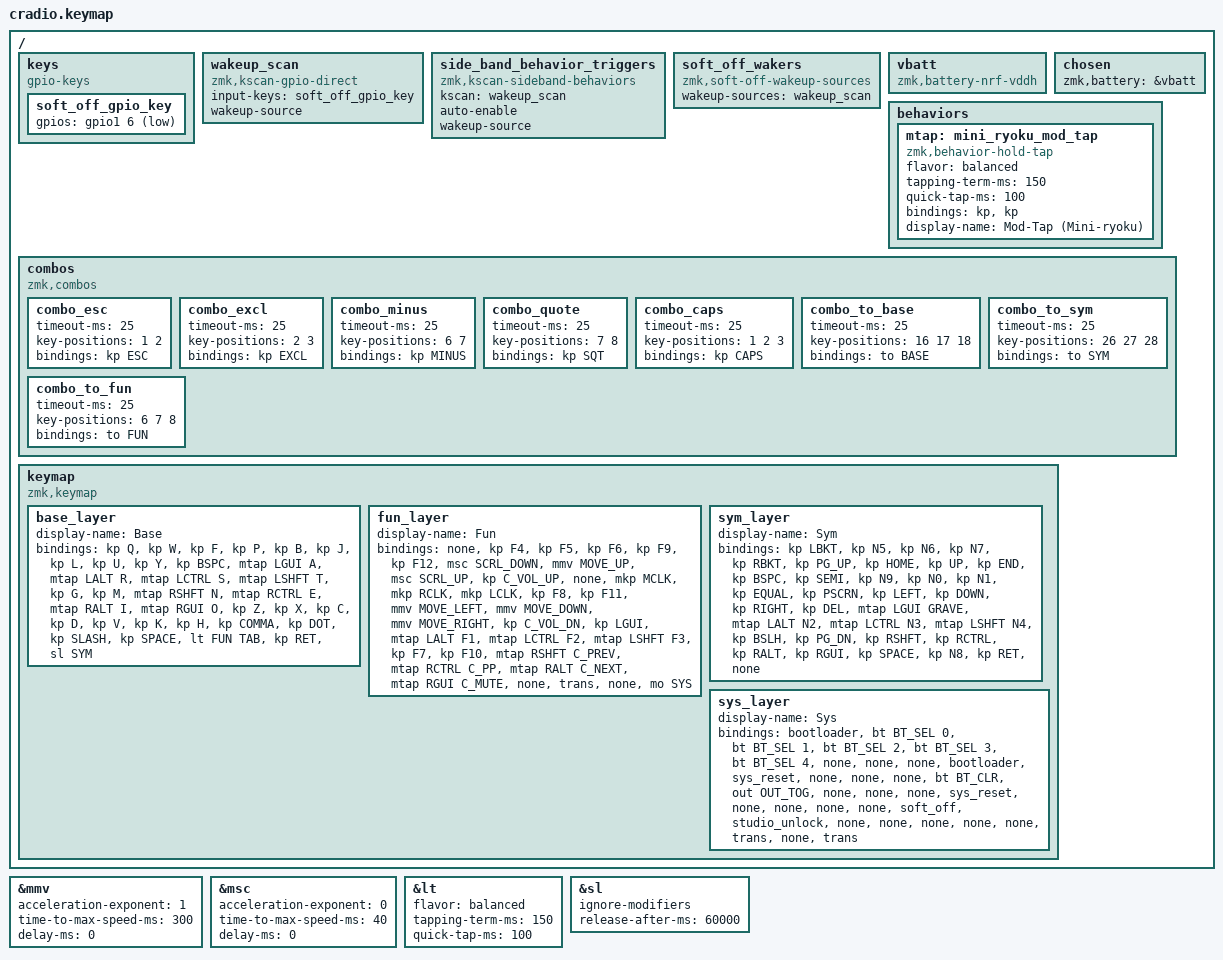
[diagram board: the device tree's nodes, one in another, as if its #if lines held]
// Mini-ryoku for the Ferris Sweep (cradio), ZMK port.
//
// Layout: Mini-ryoku by ChuseCubr, a 34-key adaptation of Miryoku.
//   https://github.com/ChuseCubr/mini-ryoku (branch `combos`, commit 7a710dd)
//   Copyright 2023 ChuseCubr, GPL-2.0-or-later.
// This file is a hand port of its QMK keymap (qmk/layout.h, keycodes.h,
// combos.c, config.h) to ZMK, and is distributed under the same licence:
// GNU General Public License, version 2 or (at your option) any later version.
// Deviations from upstream are listed in README.md.
//
// Hardware nodes (soft-off wakeup, battery) and pointer speed come from the
// NXTKB Ferris Sweep stock keymap:
// Copyright (c) 2022 The ZMK Contributors
// SPDX-License-Identifier: MIT

// Optional: home-row mods instead of Mini-ryoku's bottom-row mods.
// Uncomment to move the BASE layer's mods to the home row
// (A R S T = Gui Alt Ctrl Shift, N E I O = Shift Ctrl Alt Gui) and make the
// BASE bottom row plain keys (V loses its Ctrl too). FUN and SYM keep their
// bottom-row mods either way.
// #define MINIRYOKU_HOME_ROW_MODS

#define ZMK_POINTING_DEFAULT_MOVE_VAL 2500  // 600
#define ZMK_POINTING_DEFAULT_SCRL_VAL 20    // 10

#include <behaviors.dtsi>
#include <dt-bindings/zmk/bt.h>
#include <dt-bindings/zmk/keys.h>
#include <dt-bindings/zmk/outputs.h>
#include <dt-bindings/zmk/pointing.h>

#define BASE 0
#define FUN 1
#define SYM 2
#define SYS 3

// https://zmk.dev/docs/development/hardware-integration/soft-off-setup?advanced-methods=wakeup&kscan-type=dkscan
/ {
    keys {
        compatible = "gpio-keys";
        soft_off_gpio_key: soft_off_gpio_key {
            gpios = <&gpio1 6 (GPIO_ACTIVE_LOW | GPIO_PULL_UP)>;
        };
    };
    wakeup_scan: wakeup_scan {
        compatible = "zmk,kscan-gpio-direct";
        input-keys = <&soft_off_gpio_key>;
        wakeup-source;
    };
    side_band_behavior_triggers: side_band_behavior_triggers {
        compatible = "zmk,kscan-sideband-behaviors";
        kscan = <&wakeup_scan>;
        auto-enable;
        wakeup-source;
    };
    soft_off_wakers {
        compatible = "zmk,soft-off-wakeup-sources";
        wakeup-sources = <&wakeup_scan>;
    };
};

/ {
    vbatt: vbatt {
        compatible = "zmk,battery-nrf-vddh";
    };
    chosen {
        zmk,battery = &vbatt;
    };
};

// Mouse acceleration from the stock keymap.
&mmv {
    acceleration-exponent = <1>;
    time-to-max-speed-ms = <300>;
    delay-ms = <0>;
};

&msc {
    acceleration-exponent = <0>;
    time-to-max-speed-ms = <40>;
    delay-ms = <0>;
};

// QMK config.h: PERMISSIVE_HOLD, TAPPING_TERM 150, QUICK_TAP_TERM 100.
// PERMISSIVE_HOLD maps to ZMK's "balanced" flavor. QMK applies these to
// layer-taps too, so the stock &lt (used for Tab / FUN) gets the same values.
&lt {
    flavor = "balanced";
    tapping-term-ms = <150>;
    quick-tap-ms = <100>;
};

// OSL(_SYM). Shifted symbols are typed by holding the dedicated right-hand
// Shift on SYM, so a modifier press must not consume the one-shot layer
// (ZMK's &sl does not ignore modifiers by default; QMK's OSL does).
// QMK has no one-shot timeout here (ONESHOT_TIMEOUT unset); ZMK needs one,
// so it is set long enough not to matter in practice.
&sl {
    ignore-modifiers;
    release-after-ms = <60000>;
};

/ {
    behaviors {
        // Mod-tap for Mini-ryoku's mods (QMK MT / *_T()).
        mtap: mini_ryoku_mod_tap {
            compatible = "zmk,behavior-hold-tap";
            #binding-cells = <2>;
            flavor = "balanced";
            tapping-term-ms = <150>;
            quick-tap-ms = <100>;
            bindings = <&kp>, <&kp>;
            display-name = "Mod-Tap (Mini-ryoku)";
        };
    };

    // combos.c. QMK uses COMBO_ONLY_FROM_LAYER 0, i.e. combos are matched by
    // physical key on every layer; ZMK combos without `layers` do the same.
    combos {
        compatible = "zmk,combos";
        combo_esc {          // W + F
            timeout-ms = <25>;
            key-positions = <1 2>;
            bindings = <&kp ESC>;
        };
        combo_excl {         // F + P
            timeout-ms = <25>;
            key-positions = <2 3>;
            bindings = <&kp EXCL>;
        };
        combo_minus {        // L + U
            timeout-ms = <25>;
            key-positions = <6 7>;
            bindings = <&kp MINUS>;
        };
        combo_quote {        // U + Y
            timeout-ms = <25>;
            key-positions = <7 8>;
            bindings = <&kp SQT>;
        };
        combo_caps {         // W + F + P
            timeout-ms = <25>;
            key-positions = <1 2 3>;
            bindings = <&kp CAPS>;
        };
        combo_to_base {      // N + E + I
            timeout-ms = <25>;
            key-positions = <16 17 18>;
            bindings = <&to BASE>;
        };
        combo_to_sym {       // H + , + .
            timeout-ms = <25>;
            key-positions = <26 27 28>;
            bindings = <&to SYM>;
        };
        combo_to_fun {       // L + U + Y
            timeout-ms = <25>;
            key-positions = <6 7 8>;
            bindings = <&to FUN>;
        };
    };

    keymap {
        compatible = "zmk,keymap";

        base_layer {
            display-name = "Base";
            bindings = <
#if defined(MINIRYOKU_HOME_ROW_MODS)
            &kp Q            &kp W            &kp F             &kp P            &kp B              &kp J      &kp L             &kp U             &kp Y            &kp BSPC
            &mtap LGUI A     &mtap LALT R     &mtap LCTRL S     &mtap LSHFT T    &kp G              &kp M      &mtap RSHFT N     &mtap RCTRL E     &mtap RALT I     &mtap RGUI O
            &kp Z            &kp X            &kp C             &kp D            &kp V              &kp K      &kp H             &kp COMMA         &kp DOT          &kp SLASH
#else
            &kp Q            &kp W            &kp F             &kp P            &kp B              &kp J      &kp L             &kp U             &kp Y            &kp BSPC
            &kp A            &kp R            &kp S             &kp T            &kp G              &kp M      &kp N             &kp E             &kp I            &kp O
            &mtap LGUI Z     &mtap LALT X     &mtap LCTRL C     &mtap LSHFT D    &mtap LCTRL V      &kp K      &mtap RSHFT H     &mtap RCTRL COMMA &mtap RALT DOT   &mtap RGUI SLASH
#endif
                                                                &kp SPACE        &lt FUN TAB        &kp RET    &sl SYM
            >;
        };

        fun_layer {
            display-name = "Fun";
            bindings = <
            &none            &kp F4           &kp F5            &kp F6           &kp F9             &kp F12    &msc SCRL_DOWN    &mmv MOVE_UP      &msc SCRL_UP     &kp C_VOL_UP
            &none            &mkp MCLK        &mkp RCLK         &mkp LCLK        &kp F8             &kp F11    &mmv MOVE_LEFT    &mmv MOVE_DOWN    &mmv MOVE_RIGHT  &kp C_VOL_DN
            &kp LGUI         &mtap LALT F1    &mtap LCTRL F2    &mtap LSHFT F3   &kp F7             &kp F10    &mtap RSHFT C_PREV &mtap RCTRL C_PP &mtap RALT C_NEXT &mtap RGUI C_MUTE
                                                                &none            &trans             &none      &mo SYS
            >;
        };

        sym_layer {
            display-name = "Sym";
            bindings = <
            &kp LBKT         &kp N5           &kp N6            &kp N7           &kp RBKT           &kp PG_UP  &kp HOME          &kp UP            &kp END          &kp BSPC
            &kp SEMI         &kp N9           &kp N0            &kp N1           &kp EQUAL          &kp PSCRN  &kp LEFT          &kp DOWN          &kp RIGHT        &kp DEL
            &mtap LGUI GRAVE &mtap LALT N2    &mtap LCTRL N3    &mtap LSHFT N4   &kp BSLH           &kp PG_DN  &kp RSHFT         &kp RCTRL         &kp RALT         &kp RGUI
                                                                &kp SPACE        &kp N8             &kp RET    &none
            >;
        };

        // Not in Mini-ryoku: keyboard management. Hold Tab (FUN) with the
        // left thumb, then hold the right outer thumb.
        // &bootloader and &sys_reset act on the half whose key is pressed.
        sys_layer {
            display-name = "Sys";
            bindings = <
            &bootloader      &bt BT_SEL 0     &bt BT_SEL 1      &bt BT_SEL 2     &bt BT_SEL 3       &bt BT_SEL 4    &none        &none             &none            &bootloader
            &sys_reset       &none            &none             &none            &bt BT_CLR         &out OUT_TOG    &none        &none             &none            &sys_reset
            &none            &none            &none             &none            &soft_off          &studio_unlock  &none        &none             &none            &none
                                                                &none            &trans             &none           &trans
            >;
        };
    };
};
